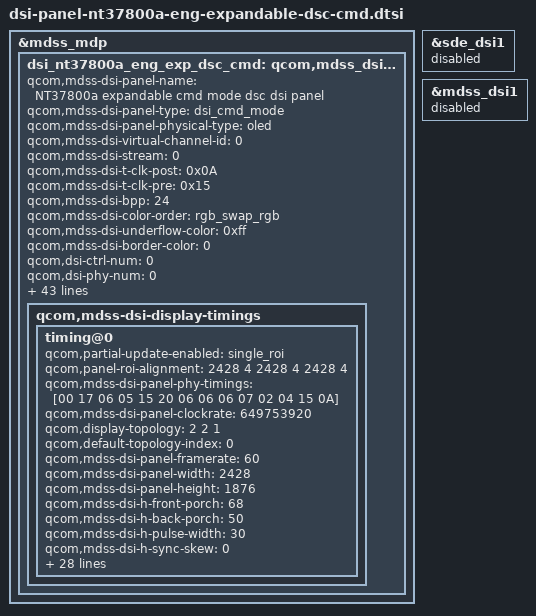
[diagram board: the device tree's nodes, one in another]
/* Copyright (c) 2014, Code Aurora Forum. All rights reserved.
 *
 * This program is free software; you can redistribute it and/or modify
 * it under the terms of the GNU General Public License version 2 and
 * only version 2 as published by the Free Software Foundation.
 *
 * This program is distributed in the hope that it will be useful,
 * but WITHOUT ANY WARRANTY; without even the implied warranty of
 * MERCHANTABILITY or FITNESS FOR A PARTICULAR PURPOSE.  See the
 * GNU General Public License for more details.
 */

&mdss_mdp {
    dsi_nt37800a_eng_exp_dsc_cmd: qcom,mdss_dsi_nt37800a_eng_exp_dsc_cmd {
    qcom,mdss-dsi-panel-name = "NT37800a expandable cmd mode dsc dsi panel";
		qcom,mdss-dsi-panel-type = "dsi_cmd_mode";
		qcom,mdss-dsi-panel-physical-type = "oled";
		qcom,mdss-dsi-virtual-channel-id = <0>;
		qcom,mdss-dsi-stream = <0>;
		qcom,mdss-dsi-t-clk-post = <0x0A>;
		qcom,mdss-dsi-t-clk-pre = <0x15>;
		qcom,mdss-dsi-bpp = <24>;
		qcom,mdss-dsi-color-order = "rgb_swap_rgb";
		qcom,mdss-dsi-underflow-color = <0xff>;
		qcom,mdss-dsi-border-color = <0>;
		qcom,dsi-ctrl-num = <0>;
		qcom,dsi-phy-num = <0>;
		qcom,dsi-select-clocks = "mux_byte_clk0", "mux_pixel_clk0";
		qcom,mdss-dsi-traffic-mode = "burst_mode";
		qcom,mdss-dsi-lane-map = "lane_map_0123";
		qcom,mdss-dsi-bllp-eof-power-mode;
		qcom,mdss-dsi-bllp-power-mode;
		qcom,mdss-dsi-lane-0-state;
		qcom,mdss-dsi-lane-1-state;
		qcom,mdss-dsi-lane-2-state;
		qcom,mdss-dsi-lane-3-state;
		qcom,mdss-dsi-reset-sequence = <1 10>, <0 2>, <1 10>;
		lge,mdss-dsi-reset-keep-high-after-off-cmd = <180>;
		qcom,mdss-dsi-dma-trigger = "trigger_sw";
		qcom,mdss-dsi-mdp-trigger = "none";
		qcom,mdss-dsi-te-pin-select = <1>;
		qcom,mdss-dsi-wr-mem-start = <0x2c>;
		qcom,mdss-dsi-wr-mem-continue = <0x3c>;
		qcom,mdss-dsi-te-dcs-command = <1>;
		//qcom,mdss-dsi-te-check-enable;
		//qcom,mdss-dsi-te-using-te-pin;
		qcom,mdss-dsi-lp11-init;
		qcom,mdss-dsi-tx-eot-append;
		qcom,ulps-enabled;

		/***************************** HDR *******************************/
		qcom,mdss-dsi-panel-hdr-enabled;
		qcom,mdss-dsi-panel-hdr-color-primaries = <14500 15500 32000
			17000 15500 30000 8000 3000>;
		qcom,mdss-dsi-panel-peak-brightness = <4200000>;
		qcom,mdss-dsi-panel-blackness-level = <3230>;

		qcom,mdss-pan-physical-width-dimension = <156>;
		qcom,mdss-pan-physical-height-dimension = <121>;

		/************************ Brightness ******************************/
		//lge,use-dim-ctrl;
		/* Brightness Map List */
		lge,blmap = <
			0
			5 5 5 5 5 5 5 5 5 5 6 6 7 7 8 8 9 9 10 10
			11 11 12 12 13 13 14 14 15 15 16 16 17 17 18 18 20 21 23 24
			26 28 29 31 32 34 36 37 39 40 42 44 45 47 48 50 52 53 55 56
			58 61 64 67 70 72 75 78 81 84 87 90 93 95 98 101 104 107 110 113
			116 120 125 130 127 132 136 141 146 151 155 160 165 170 174 179 184 189 193 198
			203 208 212 217 222 227 231 236 241 247 252 258 263 269 274 279 285 290 296 301
			307 312 317 323 328 334 339 344 350 355 361 366 372 377 385 392 400 408 415 423
			430 436 444 451 459 466 474 482 489 497 505 512 520 528 535 543 551 558 568 577
			586 596 605 614 623 632 642 651 660 669 679 688 697 706 715 725 734 743 752 761
			771 780 789 801 812 824 836 847 859 870 882 894 905 917 929 940 952 963 975 987
			998 1010 1022 1033 1045 1056 1068 1079 1090 1102 1113 1124 1135 1146 1158 1169 1180 1191 1202 1214
			1225 1236 1247 1258 1270 1281 1292 1303 1314 1326 1337 1348 1364 1379 1395 1410 1426 1441 1457 1472
			1488 1503 1519 1534 1550 1565 1581 1596 1612 1627 1643 1658 1674 1689 1705 1708 1710 1713 1715 1718
			1720 1723 1725 1728 1730 1733 1735 1738 1740 1743 1745 1748 1750 1753 1755 1758 1762 1765 1768 1772
			1775 1778 1782 1785 1788 1792 1795 1798 1802 1805 1808 1812 1815 1818 1822 1825 1828 1832 1835 1838
			1842 1845 1848 1852 1855 1858 1862 1865 1868 1872 1875 1878 1882 1885 1888 1892 1895 1898 1902 1905
			1908 1912 1915 1918 1922 1925 1928 1932 1935 1938 1942 1945 1948 1952 1955 1958 1962 1965 1968 1972
			1975 1978 1982 1985 1988 1992 1995 1998 2002 2005 2008 2011 2013 2016 2019 2022 2025 2027 2030 2033
			2036 2039 2041 2044 2047
		>;

		lge,blmap-ex = <
			0
			16 16 16 16 16 16 16 16 16 25 35 44 53 62 72 81 90 99 109 118
			127 136 146 155 164 173 183 192 201 210 220 229 238 247 257 266 273 281 288 295
			303 310 317 325 332 339 347 354 361 369 376 383 391 398 405 413 420 427 435 442
			449 457 464 471 479 486 493 501 508 515 523 530 537 545 552 572 592 612 632 652
			672 692 712 732 752 772 792 812 832 852 872 892 912 932 952 972 992 1009 1026 1043
			1060 1076 1093 1110 1127 1144 1161 1178 1195 1212 1228 1245 1262 1279 1296 1310 1325 1339 1353 1368
			1382 1396 1411 1425 1439 1453 1468 1482 1496 1511 1525 1539 1554 1568 1568 1568 1568 1568 1568 1568
			1589 1611 1632 1653 1674 1696 1717 1738 1759 1781 1802 1823 1844 1866 1887 1908 1929 1951 1972 1972
			1972 1972 1972 1972 1972 1972 1972 1972 1972 1972 1972 1972 1972 1972 1972 1972 1972 1972 1972 1972
			1972 1972 1972 1972 1972 1972 1972 1972 1972 1972 1972 1972 1972 1972 1972 1972 1972 1972 1972 1972
			1972 1972 1972 1972 1972 1972 1972 1972 1972 1972 1972 1972 1972 1972 1972 1972 1972 1972 1972 1972
			1972 1972 1972 1972 1972 1972 1972 1972 1972 1972 1972 1972 1972 1972 1972 1972 1972 1972 1972 1972
			1972 1972 1972 1972 1972 1972 1972 1972 1972 1972 1972 1972 1972 1972 1972
		>;

		/*************************** AOD **********************************/
		lge,use-ambient;
		lge,aod-interface-data = "partial", "partial", "partial";
		lge,update-pps-in-lp-mode;
		lge,mdss-dsi-nolp-command = [
			05 01 00 00 00 00 01 38
		];
		lge,mdss-dsi-nolp-command-state = "dsi_lp_mode";
		lge,mdss-dsi-lp2-command = [
			05 01 00 00 00 00 01 39
		];
		lge,mdss-dsi-lp2-command-state = "dsi_lp_mode";

		qcom,mdss-dsi-display-timings {
			timing@0{
				qcom,partial-update-enabled = "single_roi";
				qcom,panel-roi-alignment = <2428 4 2428 4 2428 4>;
				qcom,mdss-dsi-panel-phy-timings = [00 17 06 05 15 20 06 06 06 07 02 04 15 0A]; /* To Do */
				qcom,mdss-dsi-panel-clockrate = <649753920>;
				qcom,display-topology = <2 2 1>;
				qcom,default-topology-index = <0>;
				qcom,mdss-dsi-panel-framerate = <60>;
				qcom,mdss-dsi-panel-width = <2428>;
				qcom,mdss-dsi-panel-height = <1876>;
				qcom,mdss-dsi-h-front-porch = <68>;
				qcom,mdss-dsi-h-back-porch = <50>;
				qcom,mdss-dsi-h-pulse-width = <30>;
				qcom,mdss-dsi-h-sync-skew = <0>;
				qcom,mdss-dsi-v-back-porch = <2>;
				qcom,mdss-dsi-v-front-porch = <4>;
				qcom,mdss-dsi-v-pulse-width = <2>;
				qcom,mdss-dsi-h-left-border = <0>;
				qcom,mdss-dsi-h-right-border = <0>;
				qcom,mdss-dsi-v-top-border = <0>;
				qcom,mdss-dsi-v-bottom-border = <0>;
				qcom,mdss-dsi-h-sync-pulse = <0>;
				//qcom,mdss-mdp-transfer-time-us = <15000>;

				qcom,mdss-dsi-on-command = [
					39 01 00 00 00 00 06 F0 55 AA 52 00 00
					39 01 00 00 00 00 05 FF AA 55 A5 80
					15 01 00 00 00 00 02 6F 50
					15 01 00 00 00 00 02 FB 00
					39 01 00 00 00 00 05 FF AA 55 A5 81
					39 01 00 00 00 00 05 FF AA 55 A5 00
					15 01 00 00 00 00 02 35 00
					39 01 00 00 00 00 05 3B 00 10 00 10
					15 01 00 00 00 00 02 53 20
					39 01 00 00 00 00 05 51 00 00 0F FF
					15 01 00 00 00 00 02 03 01
					39 01 00 00 00 00 05 2A 00 00 09 7B
					39 01 00 00 00 00 05 2B 00 00 07 53
					15 01 00 00 00 00 02 90 81
					39 01 00 00 00 00 13 91 89 28 00 04 02 00 01 00 01 B9 00 10 00 00 0B 25 10 D0
					15 01 00 00 00 00 02 2C 00
					05 01 00 00 78 00 01 11
					05 01 00 00 00 00 01 29
					];

				qcom,mdss-dsi-post-panel-on-command = [
					//05 01 00 00 78 00 01 12
					//39 01 00 00 00 00 03 51 07 FF
				];

				qcom,mdss-dsi-off-command = [
					05 01 00 00 00 00 01 28
					05 01 00 00 20 00 01 10
				];

				qcom,compression-mode = "dsc";
				qcom,mdss-dsc-version = <0x11>;
				qcom,mdss-dsc-scr-version = <0x1>;
				qcom,mdss-dsc-slice-height = <4>;
				qcom,mdss-dsc-slice-width = <1214>;
				qcom,mdss-dsc-slice-per-pkt = <2>;
				qcom,mdss-dsc-bit-per-component = <8>;
				qcom,mdss-dsc-bit-per-pixel = <8>;
				qcom,lm-split = <1214 1214>;
				qcom,mdss-dsc-encoders = <2>;
				qcom,mdss-dsc-block-prediction-enable;

				qcom,mdss-dsi-on-command-state = "dsi_lp_mode";
				qcom,mdss-dsi-off-command-state = "dsi_lp_mode";

				qcom,mode-control-dsi-state = "dsi_lp_mode";
				qcom,mdss-dsi-pps-command-state = "dsi_hs_mode";
			};
		};
	};
};

&sde_dsi1 {
	status = "disabled";
};

&mdss_dsi1 {
	status = "disabled";
};
